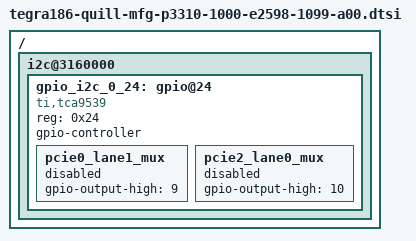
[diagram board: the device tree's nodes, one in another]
/*
 * tegra186-quill-mfg-p3310-1000-e2598-1099-a00.dtsi
 *
 * Copyright (c) 2016, NVIDIA CORPORATION.  All rights reserved.
 *
 * This program is free software; you can redistribute it and/or modify
 * it under the terms of the GNU General Public License as published by
 * the Free Software Foundation; version 2 of the License.
 *
 * This program is distributed in the hope that it will be useful, but WITHOUT
 * ANY WARRANTY; without even the implied warranty of MERCHANTABILITY or
 * FITNESS FOR A PARTICULAR PURPOSE.  See the GNU General Public License for
 * more details.
 */

#include <dt-bindings/gpio/tegra-gpio.h>
#include <dt-bindings/input/input.h>

/ {
	i2c@3160000 {
		gpio_i2c_0_24: gpio@24 {
			compatible = "ti,tca9539";
			reg = <0x24>;
			gpio-controller;
			#gpio-cells = <2>;
			pcie0_lane1_mux: pcie0_lane1_mux {
				gpio-output-high = <9>;
				status = "disabled";
			};
			pcie2_lane0_mux: pcie2_lane0_mux {
				gpio-output-high = <10>;
				status = "disabled";
			};
		};
	};
};
